# DDR_PHY register map
Vendor: Texas Instruments
Registers are 32-bit, access per field, reset 0x0 unless marked. A register's access mark holds for its fields unless they carry their own. Offsets are as the file gives them; [hi:lo] are bit positions; {n}, {i} and the like mark numbered series; 'fields as' and 'values as' point back to an identical list.

## DDR_PHY
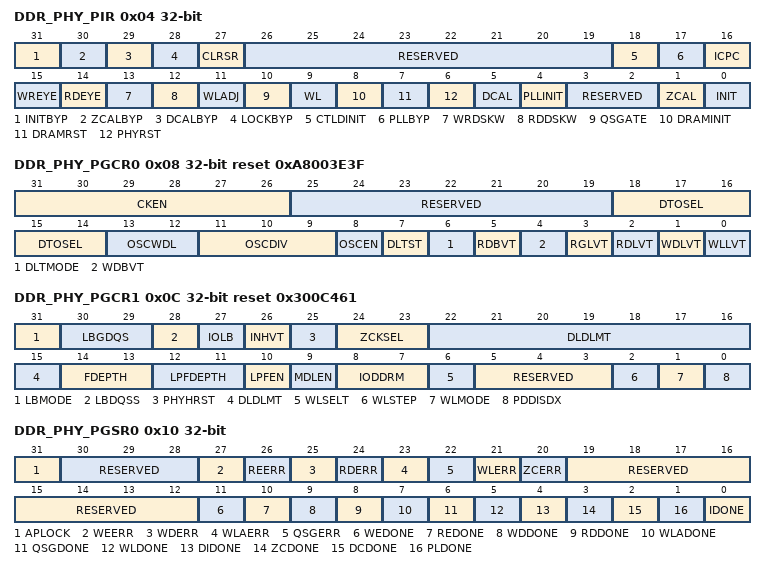
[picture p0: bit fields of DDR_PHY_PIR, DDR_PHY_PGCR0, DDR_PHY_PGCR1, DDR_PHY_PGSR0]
0x04 DDR_PHY_PIR
  [31] INITBYP rw — Initialization Bypass: Bypasses or stops, if set, all initialization routines currently running, including PHY initialization, DRAM initialization, and PHY training. Initialization may be triggered manually using INIT and the other relevant bits of the
  [30] ZCALBYP rw — Impedance Calibration Bypass: Bypasses or stops, if set, impedance calibration of all ZQ control blocks that automatically triggers after reset. Impedance calibration may be triggered manually using INIT and ZCAL bits of the
  [29] DCALBYP rw — Digital Delay Line (DDL) Calibration Bypass: Bypasses or stops, if set, DDL calibration that automatically triggers after reset. DDL calibration may be triggered manually using INIT and DCAL bits of the
  [28] LOCKBYP rw — PLL Lock Bypass: Bypasses or stops, if set, the waiting of PLLs to lock. PLL lock wait is automatically triggered after reset. PLL lock wait may be triggered manually using INIT and PLLLOCK bits of the
  [27] CLRSR rw — Clear Status Registers: A write of '1' to this bit will clear (reset to ‘0’) all status registers, including PGSR and DXnGSR. The clear status register bit is self-clearing. Note, this bit does not clear the PGSR.IDONE bit. If the IDONE bit is set it remains at 1’b1 to indicate the PUB has competed its task. This bit is primarily for debug purposes and is typically not needed during normal functional operation. It can be used when PGSR.IDONE=1, to manually clear the PGSR status bits, although starting a new init process will automatically clear the PGSR status bits. Or it can be used to manually clear the DXnGSR status bits, although starting a new data training process will automatically clear the DXnGSR status bits.
  [26:19] RESERVED ro — Returns zeros on reads.
  [18] CTLDINIT rw — Controller DRAM Initialization: Indicates if set that DRAM initialization will be performed by the controller. Otherwise if not set it indicates that DRAM initialization will be performed using the built-in initialization sequence or using software through the configuration port.
  [17] PLLBYP rw — PLL Bypass: A setting of 1 on this bit will put all PHY PLLs in bypass mode.
  [16] ICPC rw — Initialization Complete Pin Configuration: Specifies how the DFI initialization complete output pin (dfi_init_complete) should be used to indicate the status of initialization. Valid value are:
  [15] WREYE rw — Write Data Eye Training: Executes a PUB training routine to maximize the write data eye.
  [14] RDEYE rw — Read Data Eye Training: Executes a PUB training routine to maximize the read data eye.
  [13] WRDSKW rw — Write Data Bit Deskew: Executes a PUB training routine to deskew the DQ bits during write
  [12] RDDSKW rw — Read Data Bit Deskew: Executes a PUB training routine to deskew the DQ bits during read
  [11] WLADJ rw — Write Leveling Adjust (DDR3 Only): Executes a PUB training routine that readjusts the write latency used during write in case the write leveling routine changed the expected latency.
  [10] QSGATE rw — Read DQS Gate Training: Executes a PUB training routine to determine the optimum position of the read data DQS strobe for maximum system timing margins
  [9] WL rw — Write Leveling (DDR3 Only): Executes a PUB write leveling routine.
  [8] DRAMINIT rw — DRAM Initialization: Executes the DRAM initialization sequence
  [7] DRAMRST rw — DRAM Reset: Issues a reset to the DRAM (by driving the DRAM reset pin low) and wait 200us. This can be triggered in isolation or with the full DRAM initialization (DRAMINIT). For the later case, the reset is issued and 200us is waited before starting the full initialization sequence.
  [6] PHYRST rw — PHY Reset: Resets the AC and DATX8 modules by asserting the AC/DATX8 reset pin.
  [5] DCAL rw — Digital Delay Line (DDL) Calibration: Performs PHY delay line calibration.
  [4] PLLINIT rw — PLL Initialization: Executes the PLL initialization sequence which includes correct driving of PLL power-down, reset and gear shift pins, and then waiting for the PHY PLLs to lock.
  [3:2] RESERVED ro — Returns zeros on reads
  [1] ZCAL rw — Impedance Calibration: Performs PHY impedance calibration. When set the impedance calibration will be performed in parallel with PHY initialization (PLL initialization + DDL calibration + PHY reset).
  [0] INIT rw — Initialization Trigger: A write of '1' to this bit triggers the DDR system initialization, including PHY initialization, DRAM initialization, and PHY training. The exact initialization steps to be executed are specified in bits 1 to 15 of this register. A bit setting of 1 means the step will be executed as part of the initialization sequence, while a setting of ‘0’ means the step will be bypassed. The initialization trigger bit is self-clearing.
0x08 DDR_PHY_PGCR0 reset 0xA8003E3F
  [31:26] CKEN rw — CK Enable: Controls whether the CK going to the SDRAM is enabled (toggling) or disabled (static value) and whether the CK is inverted. Two bits for each of the up to three CK pairs. Valid values for the two bits are: TI recommends that this field be always programmed to 101010b.
  [25:19] RESERVED ro — Returns zeros on reads.
  [18:14] DTOSEL rw — Digital Test Output Select: Selects the PHY digital test output that should be driven onto PHY digital test output (phy_dto) pin: Valid values are:
  [13:12] OSCWDL rw — Oscillator Mode Write-Leveling Delay Line Select: Selects which of the two write leveling LCDLs is active. The delay select value of the inactive LCDL is set to zero while the delay select value of the active LCDL can be varied by the input write leveling delay select pin. Valid values are:
  [11:9] OSCDIV rw — Oscillator Mode Division: Specifies the factor by which the delay line oscillator mode output is divided down before it is output on the delay line digital test output pin dl_dto. Valid values are:
  [8] OSCEN rw — Oscillator Enable: Enables, if set, the delay line oscillation.
  [7] DLTST rw — Delay Line Test Start: A write of '1' to this bit will trigger delay line oscillator mode period measurement. This bit is not self clearing and needs to be reset to '0' before the measurement can be re-triggered.
  [6] DLTMODE rw — Delay Line Test Mode: Selects, if set, the delay line oscillator test mode.
  [5] RDBVT rw — Read Data BDL VT Compensation: Enables, if set the VT drift compensation of the read data bit delay lines
  [4] WDBVT rw — Write Data BDL VT Compensation: Enables, if set the VT drift compensation of the write data bit delay lines.
  [3] RGLVT rw — Read DQS Gating LCDL Delay VT Compensation: Enables, if set the VT drift compensation of the read DQS gating LCDL
  [2] RDLVT rw — Read DQS LCDL Delay VT Compensation: Enables, if set the VT drift compensation of the read DQS LCDL.
  [1] WDLVT rw — Write DQ LCDL Delay VT Compensation: Enables, if set the VT drift compensation of the write DQ LCDL.
  [0] WLLVT rw — Write Leveling LCDL Delay VT Compensation: Enables, if set, the VT drift compensation of the write leveling LCDL
0x0C DDR_PHY_PGCR1 reset 0x300C461
  [31] LBMODE rw — Loopback Mode: Indicates, if set, that the PHY/PUB is in loopback mode
  [30:29] LBGDQS rw — Loopback DQS Gating: Selects the DQS gating mode that should be used when the PHY is in loopback mode, including BIST loopback mode. Valid values are:
  [28] LBDQSS rw — Loopback DQS Shift: Selects how the read DQS is shifted during loopback to ensure that the read DQS is centered into the read data eye. Valid values are:
  [27] IOLB rw — I/O Loop-Back Select: Selects where inside the I/O the loop-back of signals happens. Valid values are:
  [26] INHVT rw — VT Calculation Inhibit: Inhibits calculation of the next VT compensated delay line values. A value of 1 will inhibit the VT calculation. This bit should be set to 1 during writes to the delay line registers. This bit should NOT be set to 1 until after PHY initialization completes
  [25] PHYHRST rw — PHY High-Speed Reset: A write of ‘0’ to this bit resets the AC and DATX8 macros without resetting PUB RTL logic. This bit is not self-clearing and a ‘1’ must be written to de-assert the reset
  [24:23] ZCKSEL rw — Impedance Clock Divider Select: Selects the divide ratio for the clock used by the impedance control logic relative to the clock used by the memory controller and SDRAM. Valid values are: TI recommends that this field be always programmed to 01b.
  [22:15] DLDLMT rw — Delay Line VT Drift Limit: Specifies the minimum change in the delay line VT drift in one direction which should result in the assertion of the delay line VT drift status signal (vt_drift). The limit is specified in terms of delay select values. A value of 0 disables the assertion of delay line VT drift status signal.
  [14:13] FDEPTH rw — Filter Depth: Specifies the number of measurements over which all AC and DATX8 initial period measurements, that happen after reset or when calibration is manually triggered, are averaged. Valid values are:
  [12:11] LPFDEPTH rw — Low-Pass Filter Depth: Specifies the number of measurements over which MDL period measurements are filtered. This determines the time constant of the low pass filter. Valid values are:
  [10] LPFEN rw — Low-Pass Filter Enable: Enables, if set, the low pass filtering of MDL period measurements.
  [9] MDLEN rw — Master Delay Line Enable: Enables, if set, the AC master delay line calibration to perform subsequent period measurements following the initial period measurements that are performed after reset or on when calibration is manually triggered. These additional measurements are accumulated and filtered as long as this bit remains high.
  [8:7] IODDRM rw — This field should be programmed to 1h if using DDR3 and 2h if using DDR3L.
  [6] WLSELT rw — Write Leveling Select Type: Selects the encoding type for the write leveling select signal depending on the desired setup/hold margins for the internal pipelines. Valid values are:
  [5:3] RESERVED ro — Return zeros on reads.
  [2] WLSTEP rw — Write Leveling Step: Specifies the number of delay step-size increments during each step of write leveling. Valid values are:
  [1] WLMODE rw — Write Leveling (Software) Mode: Indicates if set that the PHY is in software write leveling mode in which software executes single steps of DQS pulsing by writing '1' to
  [0] PDDISDX rw — Power Down Disabled Byte: Indicates if set that the PLL and I/Os of a disabled byte should be powered down
0x10 DDR_PHY_PGSR0 ro
  [31] APLOCK — AC PLL Lock: Indicates, if set, that AC PLL has locked. This is a direct status of the AC PLL lock pin
  [30:28] RESERVED — Returns zeros on reads.
  [27] WEERR — Write Eye Training Error: Indicates if set that there is an error in write eye training.
  [26] REERR — Read Eye Training Error: Indicates if set that there is an error in read eye training
  [25] WDERR — Write Bit Deskew Error: Indicates if set that there is an error in write bit deskew
  [24] RDERR — Read Bit Deskew Error: Indicates if set that there is an error in read bit deskew
  [23] WLAERR — Write Leveling Adjustment Error: Indicates if set that there is an error in write leveling adjustment
  [22] QSGERR — DQS Gate Training Error: Indicates if set that there is an error in DQS gate training.
  [21] WLERR — Write Leveling Error: Indicates if set that there is an error in write leveling.
  [20] ZCERR — Impedance Calibration Error: Indicates if set that there is an error in impedance calibration.
  [19:12] RESERVED — Returns zeros on reads.
  [11] WEDONE — Write Eye Training Done: Indicates if set that write eye training has completed
  [10] REDONE — Read Eye Training Done: Indicates if set that read eye training has completed
  [9] WDDONE — Write Bit Deskew Done: Indicates if set that write bit deskew has completed.
  [8] RDDONE — Read Bit Deskew Done: Indicates if set that read bit deskew has completed
  [7] WLADONE — Write Leveling Adjustment Done: Indicates if set that write leveling adjustment has completed
  [6] QSGDONE — DQS Gate Training Done: Indicates if set that DQS gate training has completed.
  [5] WLDONE — Write Leveling Done: Indicates if set that write leveling has completed.
  [4] DIDONE — DRAM Initialization Done: Indicates if set that DRAM initialization has completed
  [3] ZCDONE — Impedance Calibration Done: Indicates if set that impedance calibration has completed
  [2] DCDONE — Digital Delay Line (DDL) Calibration Done: Indicates if set that DDL calibration has completed
  [1] PLDONE — PLL Lock Done: Indicates if set that PLL locking has completed.
  [0] IDONE — Initialization Done: Indicates if set that the DDR system initialization has completed. This bit is set after all the selected initialization routines in
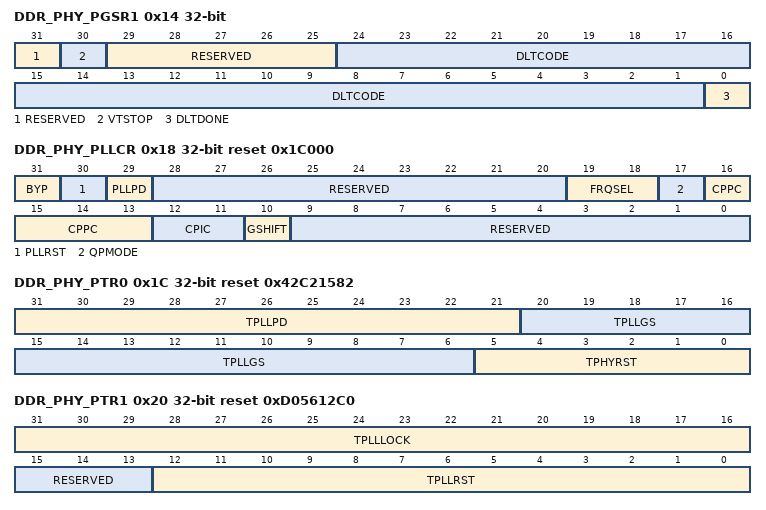
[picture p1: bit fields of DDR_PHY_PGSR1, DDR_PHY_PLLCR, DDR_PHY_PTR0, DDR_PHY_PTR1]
0x14 DDR_PHY_PGSR1 ro
  [31] RESERVED — Returns zeros on reads.
  [30] VTSTOP — VT Stop: Indicates if set that the VT calculation logic has stopped computing the next values for the VT compensated delay line values. After assertion of the PGCR.INHVT, the VTSTOP bit should be read to ensure all VT compensation logic has stopped computations before writing to the delay line registers
  [29:25] RESERVED — Returns zeros on reads.
  [24:1] DLTCODE — Delay Line Test Code: Returns the code measured by the PHY control block that corresponds to the period of the AC delay line digital test output.
  [0] DLTDONE — Delay Line Test Done: Indicates, if set, that the PHY control block has finished doing period measurement of the AC delay line digital test output
0x18 DDR_PHY_PLLCR reset 0x1C000
  [31] BYP rw — PLL Bypass: Bypasses the PLL if set to 1.
  [30] PLLRST rw — PLL Rest: Resets the PLLs by driving the PLL reset pin. This bit is not self-clearing and a ‘0’ must be written to de-assert the reset.
  [29] PLLPD rw — PLL Power Down: Puts the PLLs in power down mode by driving the PLL power down pin. This bit is not self-clearing and a ‘0’ must be written to de-assert the power-down
  [28:20] RESERVED ro — Returns zeros on reads.
  [19:18] FRQSEL rw — PHY PLL reference frequency select: Selects the operating range of the PHY PLL. Valid values are:
  [17] QPMODE rw — PLL Quadrature Phase Mode: Enables, if set, the quadrature phase clock outputs. This mode is not used in this version of the PHY
  [16:13] CPPC rw — Charge Pump Proportional Current Control
  [12:11] CPIC rw — Charge Pump Integrating Current Control
  [10] GSHIFT ro — Gear Shift: Enables, if set, rapid locking mode.
  [9:0] RESERVED ro — Reads return zeros
0x1C DDR_PHY_PTR0 rw reset 0x42C21582
  [31:21] TPLLPD — PLL Power-Down Time: Number of VBUSP_CLK cycles that the PLL must remain in power-down mode, that is, number of clock cycles from when PLL power-down pin is asserted to when PLL power-down pin is de-asserted. This must correspond to a value that is equal to or more than 1us. Default value corresponds to 1us.
  [20:6] TPLLGS — PLL Gear Shift Time: Number of VBUSP_CLK cycles from when the PLL reset pin is de-asserted to when the PLL gear shift pin is de-asserted. This must correspond to a value that is equal to or more than 4us. Default value corresponds to 4us.
  [5:0] TPHYRST — PHY Reset Time: Number of VBUSP_CLK cycles that the PHY reset must remain asserted after PHY calibration is done before the reset to the PHY is de-asserted. This is used to extend the reset to the PHY so that the reset is asserted for some clock cycles after the clocks are stable. TI recommends setting this to 15.
0x20 DDR_PHY_PTR1 reset 0xD05612C0
  [31:16] TPLLLOCK rw — PLL Lock Time: Number of VBUSP_CLK cycles for the PLL to stabilize and lock, that is, number of clock cycles from when the PLL reset pin is de-asserted to when the PLL has lock and is ready for use. This must correspond to a value that is equal to or more than 100us. Default value corresponds to 100us
  [15:13] RESERVED ro — Reads return zeros.
  [12:0] TPLLRST rw — PLL Reset Time: Number of VBUSP_CLK cycles that the PLL must remain in reset mode, that is, number of clock cycles from when PLL power-down pin is de-asserted and PLL reset pin is asserted to when PLL reset pin is de-asserted. This must correspond to a value that is equal to or more than 9 us. Default value corresponds to 9 us.
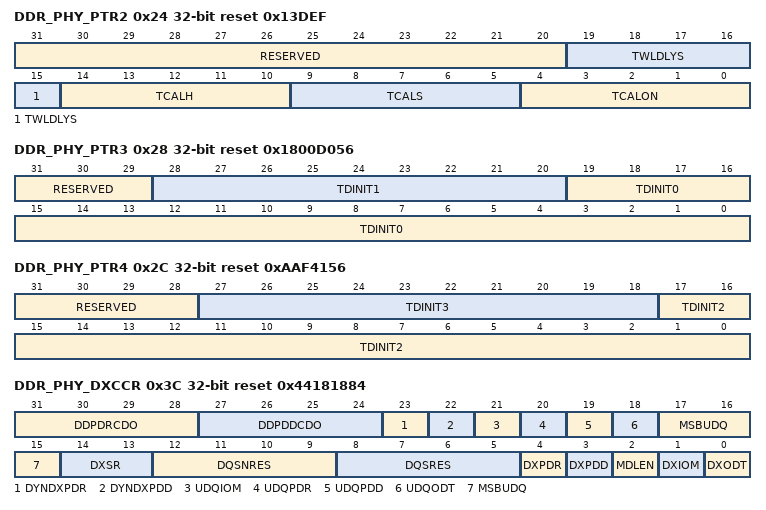
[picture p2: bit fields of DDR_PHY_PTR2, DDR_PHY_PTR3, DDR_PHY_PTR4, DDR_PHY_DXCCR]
0x24 DDR_PHY_PTR2 rw reset 0x13DEF
  [31:20] RESERVED — Reads return zeros.
  [19:15] TWLDLYS — Write Leveling Delay Settling Time: Number of controller clock cycles from when a new value of the write leveling delay is applies to the LCDL to when to DQS high is driven high. This allows the delay to settle
  [14:10] TCALH — Calibration Hold Time: Number of controller clock cycles from when the clock was disabled (cal_clk_en deasserted) to when calibration is enable (cal_en asserted).
  [9:5] TCALS — Calibration Setup Time: Number of controller clock cycles from when calibration is enabled (cal_en asserted) to when the calibration clock is asserted again (cal_clk_en asserted).
  [4:0] TCALON — Calibration On Time: Number of controller clock cycles that the calibration clock is enabled (cal_clk_en asserted).
0x28 DDR_PHY_PTR3 reset 0x1800D056
  [31:29] RESERVED ro — Reads return zeros.
  [28:20] TDINIT1 rw — DRAM Initialization Time 1: DRAM initialization time in DRAM clock cycles corresponding to the following: DDR3 = CKE high time to first command (tRFC + 10 ns or 5 tCK, whichever is bigger) Default value corresponds to DDR3 tRFC of 360ns at 1066 MHz tDINIT1 = (tCKE/tCK)-1
  [19:0] TDINIT0 rw — DRAM Initialization Time 0: DRAM initialization time in DRAM clock cycles corresponding to the following: DDR3 = CKE low time with power and clock stable (500 us)
0x2C DDR_PHY_PTR4 reset 0xAAF4156
  [31:28] RESERVED ro — Reads return zeros.
  [27:18] TDINIT3 rw — DRAM Initialization Time 3: DRAM initialization time in DRAM clock cycles corresponding to the following: DDR3 = Time from ZQ initialization command to first command (1 us) Default value corresponds to the DDR3 640ns at 1066 MHz.
  [17:0] TDINIT2 rw — DRAM Initialization Time 2: DRAM initialization time in DRAM clock cycles corresponding to the following: DDR3 = Reset low time (200 us on power-up or 100 ns after power-up) Default value corresponds to DDR3 200 us at 1066 MHz.
0x38 DDR_PHY_ACIOCR reset 0x33C03812
  [31:30] ACSR rw — Address/Command Slew Rate: Selects slew rate of the I/O for all address and command pins. 00 = very fast (use as default for DDR3 and DDR3L) 01 = fast 10 = medium 11 = slow
0x3C DDR_PHY_DXCCR rw reset 0x44181884
  [31:28] DDPDRCDO — Dynamic Data Power Down Receiver Count Down Offset: Offset applied in calculating window of time where receiver is powered up
  [27:24] DDPDDCDO — Dynamic Data Power Down Driver Count Down Offset: Offset applied in calculating window of time where driver is powered up
  [23] DYNDXPDR — Data Power Down Receiver: Dynamically powers down, when set, the input receiver on I/O for the DQ pins of the active DATX8 macros. Applies only when DXPDR and DXnGCR.DXPDR are not set to 1.
  [22] DYNDXPDD — Dynamic Data Power Down Driver: Dynamically powers down, when set, the output driver on I/O for the DQ pins of the active DATX8 macros. Applies only when DXPDD and DXnGCR.DXPDD are not set to 1.
  [21] UDQIOM — Unused DQ I/O Mode: Selects SSTL mode (when set to 0) or CMOS mode (when set to 1) of the I/O for unused DQ pins.
  [20] UDQPDR — Unused DQ Power Down Receiver: Powers down, when set, the input receiver on the I/O for unused DQ pins.
  [19] UDQPDD — Unused DQ Power Down Driver: Powers down, when set, the output driver on the I/O for unused DQ pins.
  [18] UDQODT — Unused DQ On-Die Termination: Enables, when set, the on-die termination on the I/O for unused DQ pins.
  [17:15] MSBUDQ — Most Significant Byte Unused DQs: Specifies the number of DQ bits that are not used in the most significant byte. The used (valid) bits for this byte are [8-MSBDQ- 1:0]. To disable the whole byte, use the DXnGCR.DXEN register.
  [14:13] DXSR — Data Slew Rate: Selects slew rate of the I/O for DQ, DM, and DQS/DQS# pins of all DATX8 macros. 00 = very fast (use as default for DDR3 and DDR3L) 01 = fast 10 = medium 11 = slow
  [12:9] DQSNRES — DQS# Resistor: Selects the on-die pull-up/pull-down resistor for DQS# pins. Same encoding as DQSRES.
  [8:5] DQSRES — DQS Resistor: Selects the on-die pull-down/pull-up resistor for DQS pins. DQSRES[3] selects pull-down (when set to 0) or pull-up (when set to 1). DQSRES[2:0] selects the resistor value as follows: 000 = Open: On-die resistor disconnected (use external resistor) 001 = 688 ohms 010 = 611 ohms 011 = 550 ohms 100 = 500 ohms 101 = 458 ohms 110 = 393 ohms 111 = 344 ohms
  [4] DXPDR — Data Power Down Receiver: Powers down, when set, the input receiver on I/O for DQ, DM, and DQS/DQS# pins of all DATX8 macros. This bit is ORed with the PDR configuration bit of the individual DATX8.
  [3] DXPDD — Data Power Down Driver: Powers down, when set, the output driver on I/O for DQ,DM, and DQS/DQS# pins of all DATX8 macros. This bit is ORed with the PDD configuration bit of the individual DATX8.
  [2] MDLEN — Master Delay Line Enable: Enables, if set, all DATX8 master delay line calibration to perform subsequent period measurements following the initial period measurements that are performed after reset or on when calibration is manually triggered. These additional measurements are accumulated and filtered as long as this bit remains high. This bit is ANDed with the MDLEN bit in the individual DATX8
  [1] DXIOM — Data I/O Mode: Selects SSTL mode (when set to 0) or CMOS mode (when set to 1) of the I/O for DQ, DM, and DQS/DQS# pins of all DATX8 macros. This bit is ORed with the IOM configuration bit of the individual DATX8.
  [0] DXODT — Data On-Die Termination: Enables, when set, the on-die termination on the I/O for DQ, DM, and DQS/DQS# pins of all DATX8 macros. This bit is ORed with the ODT configuration bit of the individual DATX8
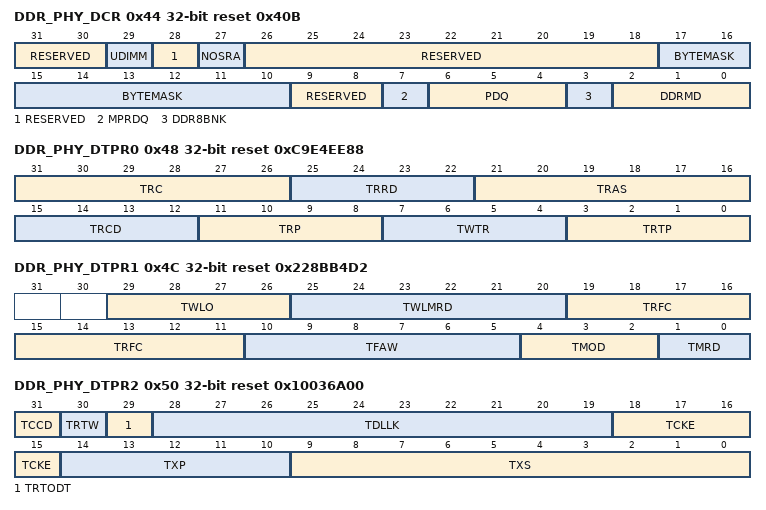
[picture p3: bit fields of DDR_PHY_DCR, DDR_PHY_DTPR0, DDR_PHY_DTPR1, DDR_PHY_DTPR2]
0x44 DDR_PHY_DCR reset 0x40B
  [31:30] RESERVED ro — Reads return zeros.
  [29] UDIMM rw — Un-buffered DIMM Address Mirroring: Indicates if set that there is address mirroring on the second rank of an un-buffered DIMM (the rank connected to CS1).
  [28] RESERVED ro — Reads return zeros.
  [27] NOSRA rw — No Simultaneous Rank Access: Specifies if set that simultaneous rank access on the same clock cycle is not allowed. This means that multiple chip select signals will not be asserted at the same time. This bit must be set if address mirroring is enabled in
  [26:18] RESERVED ro — Reads return zeros.
  [17:10] BYTEMASK rw — Byte Mask: Mask applied to all beats of read data on all bytes lanes during read DQS gate training. This allows training to be conducted based on selected bit(s) from the byte lanes. Valid values for each bit are: Note that this mask in DDR3 MPR operation mode as well and must be in keeping with the PDQ field setting. TI recommends that this field be always programmed to 0000 0001b.
  [9:8] RESERVED ro — Reads return zeros.
  [7] MPRDQ rw — Multi-Purpose Register (MPR) DQ (DDR3 Only): Specifies the value that is driven on non-primary DQ pins during MPR reads. Valid values are: TI recommends that this bit be always programmed to 0.
  [6:4] PDQ rw — Primary DQ (DDR3 Only): Specifies the DQ pin in a byte that is designated as a primary pin for Multi-Purpose Register (MPR) reads. Valid values are 0 to 7 for DQ[0] to DQ[7], respectively. TI recommends that this field be always programmed to 000b.
  [3] DDR8BNK rw — DDR 8-Bank: Indicates if set that the SDRAM used has 8 banks.
  [2:0] DDRMD rw — DDR Mode: Set to 3h for DDR3 mode.
0x48 DDR_PHY_DTPR0 rw reset 0xC9E4EE88
  [31:26] TRC — Activate to activate command delay (same bank). Valid values are 2 to 63
  [25:22] TRRD — Activate to activate command delay (different banks). Valid values are 1 to 15.
  [21:16] TRAS — Activate to precharge command delay. Valid values are 2 to 63
  [15:12] TRCD — Activate to read or write delay. Minimum time from when an activate command is issued to when a read or write to the activated row can be issued. Valid values are 2 to 15.
  [11:8] TRP — Precharge command period: The minimum time between a precharge command and any other command. Valid values are 2 to 15.
  [7:4] TWTR — Internal write to read command delay. Valid values are 1 to 15.
  [3:0] TRTP — Internal read to precharge command delay. Valid values are 2 to 15.
0x4C DDR_PHY_DTPR1 reset 0x228BB4D2
  [29:26] TWLO rw — Write leveling output delay: Number of clock cycles from when write leveling DQS is driven high by the PHY to when the results from the SDRAM on DQ is sampled by the PHY. This must include the SDRAM tWLO timing parameter plus the round trip delay from the DUT to SDRAM back to the DUT. TI recommends that this field always be programmed to 12 decimal.
  [25:20] TWLMRD rw — Minimum delay from when write leveling mode is programmed to the first DQS/DQS# rising edge
  [19:11] TRFC rw — Refresh-to-Refresh: Indicates the minimum time, in clock cycles, between two refresh commands or between a refresh and an active command. This is derived from the minimum refresh interval from the data sheet, tRFC(min), divided by the clock cycle time.
  [10:5] TFAW rw — 4-bank activate period. No more than 4-bank activate commands may be issued in a given tFAW period. Valid values are 2 to 63.
  [4:2] TMOD rw — Load mode update delay. The minimum time between a load mode register command and a non-load mode register command. Valid values are:
  [1:0] TMRD rw — Load mode cycle time: The minimum time between a load mode register command and any other command. For DDR3 this is the minimum time between two load mode register commands. the value used for tMRD is 4 plus the value programmed in these bits, that is, tMRD ranges from 4 to 7.
0x50 DDR_PHY_DTPR2 rw reset 0x10036A00
  [31] TCCD — Read to read and write to write command delay. Valid values are:
  [30] TRTW — Read to Write command delay. This parameter is only used when the PHY issues commands during initialization and leveling. During normal operation, the controller issues commands to the SDRAM and uses the timing parameters programmed in the controller. TI recommends that this bit be always set to 1 to provide additional margin during PHY initiated initialization/leveling.
  [29] TRTODT — Read to ODT delay. This parameter is only used when the PHY issues commands during initialization and leveling. During normal operation, the controller issues commands to the SDRAM and uses the timing parameters programmed in the controller. TI recommends that this bit be always set to 0.
  [28:19] TDLLK — DLL locking time. Valid values are 2 to 1023.
  [18:15] TCKE — CKE minimum pulse width. Also specifies the minimum time that the SDRAM must remain in power down or self refresh mode. This parameter must be set to the value of tCKESR which is usually bigger than the value of tCKE. Valid values are 2 to 15.
  [14:10] TXP — Power down exit delay. The minimum time between a power down exit command and any other command. This parameter must be set to the maximum of the various minimum power down exit delay parameters specified in the SDRAM data sheet, that is, max(tXP, tXPDLL). Valid values are 2 to 31.
  [9:0] TXS — Self refresh exit delay. The minimum time between a self refresh exit command and any other command. This parameter must be set to the maximum of the various minimum self refresh exit delay parameters specified in the SDRAM data sheet, that is, (tXS, tXSDLL) for DDR3. Valid values are 2 to 1023.
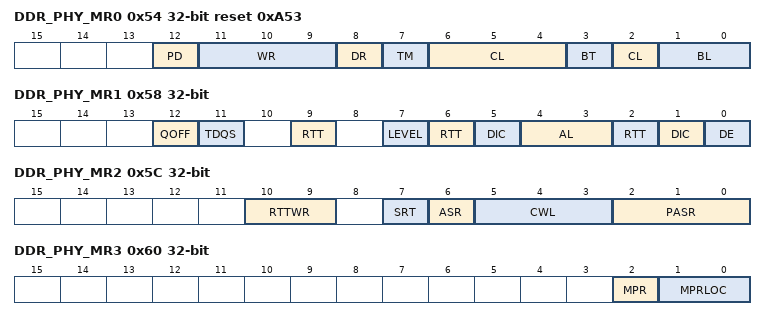
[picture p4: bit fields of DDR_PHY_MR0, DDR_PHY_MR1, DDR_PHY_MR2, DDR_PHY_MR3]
0x54 DDR_PHY_MR0 reset 0xA53
  [12] PD rw — Power-Down Control: Controls the exit time for power-down modes. This must always be set to 1.
  [11:9] WR rw — Write Recovery: This is the value of the write recovery in clock cycles. It is calculated by dividing the data sheet write recovery time, tWR (ns) by the data sheet clock cycle time, tCK (ns) and rounding up a non-integer value to the next integer. Valid values are: All other settings are reserved and should not be used.
  [8] DR rw — DLL Reset: Writing a ‘1’ to this bit will reset the SDRAM DLL. This bit is self-clearing, that is, it returns back to ‘0’ after the DLL reset has been issued.
  [7] TM rw — Operating Mode: Always set to 0 for normal operating mode.
  [6:4] CL rw — CAS Latency: The delay, in clock cycles, between SDRAM read command to data available. Valid values are: All other settings are reserved and should not be used.
  [3] BT rw — Burst type: Set to 0 for sequential burst (interleaved burst is not supported)
  [2] CL rw — This is the least significant bit of the CL field. For description, see bits [6-4].
  [1:0] BL rw — Burst Length: Determines the maximum number of column locations that can be accessed during a given read or write command. Set to 0 for a fixed burst length of 8 (other burst lengths are not supported)
0x58 DDR_PHY_MR1
  [12] QOFF rw — Output Enable/Disable: Program to ‘0’ for all outputs to function as normal.
  [11] TDQS rw — Termination Data Strobe: This must always be set to 0.
  [9] RTT rw — On Die Termination: Selects the effective resistance for SDRAM on die termination. Valid values are: All other settings are reserved and should not be used
  [7] LEVEL rw — Write Leveling Enable: Enables write-leveling when set.
  [6] RTT rw — On Die Termination: Selects the effective resistance for SDRAM on die termination. Valid values are: All other settings are reserved and should not be used
  [5] DIC rw — Output Driver Impedance Control: Controls the output drive strength. Valid values are:
  [4:3] AL rw — Posted CAS Additive Latency: the controller does not support this feature. This must always be set to 0.
  [2] RTT rw — On Die Termination: Selects the effective resistance for SDRAM on die termination. Valid values are: All other settings are reserved and should not be used
  [1] DIC rw — Output Driver Impedance Control: Controls the output drive strength. Valid values are:
  [0] DE rw — DLL Enable/Disable: Enable (0) or disable (1) the DLL. DLL must be enabled for normal operation.
0x5C DDR_PHY_MR2
  [10:9] RTTWR rw — Dynamic ODT: Selects RTT for dynamic ODT. Valid values are:
  [7] SRT rw — Self-Refresh Temperature Range: Selects either normal (‘0’) or extended (‘1’) operating temperature range during self-refresh.
  [6] ASR rw — Auto Self-Refresh: When enabled (‘1’), SDRAM automatically provides self-refresh power management functions for all supported operating temperature values. Otherwise the SRT bit must be programmed to indicate the temperature range.
  [5:3] CWL rw — CAS Write Latency: The delay, in clock cycles, between when the SDRAM registers a write command to when write data is available. Valid values are: All other settings are reserved and should not be used
  [2:0] PASR rw — Partial Array Self Refresh: Specifies that data located in areas of the array beyond the specified location will be lost if self refresh is entered.
0x60 DDR_PHY_MR3
  [2] MPR rw — Multi-Purpose Register Enable: Enables, if set, that read data should come from the Multi-Purpose Register. Otherwise read data come from the DRAM array.
  [1:0] MPRLOC rw — Multi-Purpose Register (MPR) Location: Selects MPR data location: Valid value are:
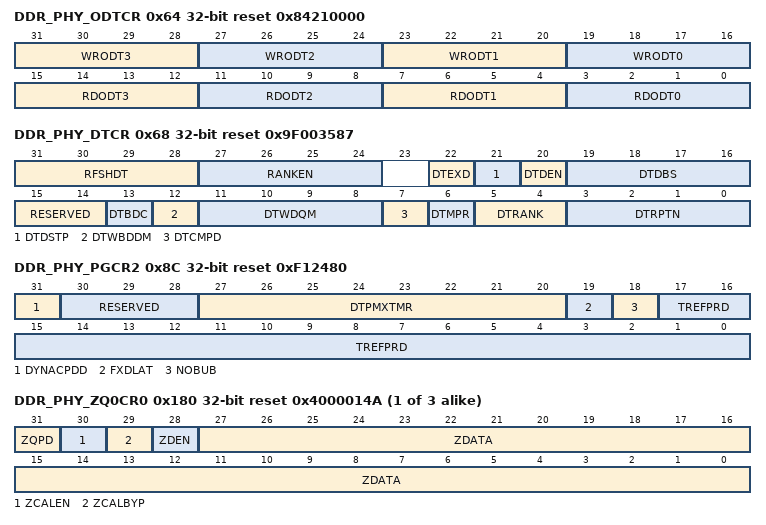
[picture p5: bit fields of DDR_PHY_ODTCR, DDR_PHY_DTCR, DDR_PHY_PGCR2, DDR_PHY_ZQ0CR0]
0x64 DDR_PHY_ODTCR rw reset 0x84210000
  [31:28] WRODT3 — Write ODT: Specifies whether ODT should be enabled (‘1’) or disabled (‘0’) on each of the up to four ranks when a write command is sent to rank n. WRODT0, WRODT1, WRODT2, and WRODT3 specify ODT settings when a write is to rank 0, rank 1, rank 2, and rank 3, respectively. The four bits of each field each represent a rank, the LSB being rank 0 and the MSB being rank 3. Default is to enable ODT only on rank being written to
  [27:24] WRODT2 — See description for WRODT3.
  [23:20] WRODT1 — See description for WRODT3.
  [19:16] WRODT0 — See description for WRODT3.
  [15:12] RDODT3 — Read ODT: Specifies whether ODT should be enabled (‘1’) or disabled (‘0’) on each of the up to four ranks when a read command is sent to rank n. RDODT0, RDODT1, RDODT2, and RDODT3 specify ODT settings when a read is to rank 0, rank 1, rank 2, and rank 3, respectively. The four bits of each field each represent a rank, the LSB being rank 0 and the MSB being rank 3. Default is to disable ODT during reads.
  [11:8] RDODT2 — See description for RDODT3.
  [7:4] RDODT1 — See description for RDODT3.
  [3:0] RDODT0 — See description for RDODT3.
0x68 DDR_PHY_DTCR reset 0x9F003587
  [31:28] RFSHDT rw — Refresh During Training: A non-zero value specifies that a burst of refreshes equal to the number specified in this field should be sent to the SDRAM after training each rank except the last rank
  [27:24] RANKEN rw — Rank Enable: Specifies the ranks that are enabled for data-training. Bit 0 controls rank 0, bit 1 controls rank 1, bit 2 controls rank 2, and bit 3 controls rank 3. Setting the bit to ‘1’ enables the rank, and setting it to ‘0’ disables the rank.
  [22] DTEXD rw — Data Training Extended Write DQS: Enables, if set, an extended write DQS whereby two additional pulses of DQS are added as post-amble to a burst of writes. Generally this should only be enabled when running read bit deskew with the intention of performing read eye deskew prior to running write leveling adjustment
  [21] DTDSTP rw — Data Training Debug Step: A write of 1 to this bit steps the data training algorithm through a single step. This bit is self-clearing
  [20] DTDEN rw — Data Training Debug Enable: Enables, if set, the data training debug mode
  [19:16] DTDBS rw — Data Training Debug Byte Select: Selects the byte during data training debug mod
  [15:14] RESERVED ro — Returns zeros on reads.
  [13] DTBDC rw — Data Training Bit Deskew Centering: Enables, if set, eye centering capability during write and read bit deskew training.
  [12] DTWBDDM rw — Data Training Write Bit Deskew Data Mask. If set it enables write bit deskew of the data mask
  [11:8] DTWDQM rw — Training WDQ Margin: Defines how close to 0 or how close to 2*(wdq calibration_value) the WDQ lcdl can be moved during training. Basically defines how much timing margin.
  [7] DTCMPD rw — Data Training Compare Data: Specifies, if set, that DQS gate training should also check if the returning read data is correct. Otherwise data-training only checks if the correct number of DQS edges were returned.
  [6] DTMPR rw — Data Training Using MPR (DDR3 Only): Specifies, if set, that DQS gate training should use the SDRAM Multi-Purpose Register (MPR) register. Otherwise data training is performed by first writing to some locations in the SDRAM and then reading them back.
  [5:4] DTRANK rw — Data Training Rank: Selects the SDRAM rank to be used during data bit deskew and eye centering
  [3:0] DTRPTN rw — Data Training Repeat Number: Repeat number used to confirm stability of DDR write or read
0x8C DDR_PHY_PGCR2 reset 0xF12480
  [31] DYNACPDD rw — Dynamic AC Power Down Driver: Powers down, when set, the output driver on I/O for the address and bank address lines
  [30:28] RESERVED ro — These bits should be always programmed to 0.
  [27:20] DTPMXTMR rw — Data Training PUB Mode Timer Exit: Specifies the number of controller clocks to wait when entering and exiting pub mode data training. The default value ensures controller refreshes do not cause memory model errors when entering and exiting data training. The value should be increased if controller initiated SDRAM ZQ short or long operation may occur just before or just after the execution of data training.
  [19] FXDLAT rw — Fixed Latency: Specified whether all reads should be returned to the controller with a fixed read latency. Enabling fixed read latency increases the read latency. Valid values are: Fixed read latency is calculated as (12 + (maximum DXnGTR.RxDGSL)/2) half data rate clock cycles.
  [18] NOBUB rw — No Bubbles: Specified whether reads should be returned to the controller with no bubbles. Enabling no-bubble reads increases the read latency. Valid values are:
  [17:0] TREFPRD rw — Refresh Period: Indicates the period in clock cycles after which the PUB has to issue a refresh command to the SDRAM. This is derived from the maximum refresh interval from the data sheet, tRFC(max) or REFI, divided by the clock cycle time. A further 400 clocks must be subtracted from the derived number to account for command flow and missed slots of refreshes in the internal PUB blocks. The default corresponds to DDR3 9*7.8us at 1066MHz (DDR3-2133) when a burst of 9 refreshes are issued at every refresh interval. TI recommends tREFPRD be programmed to 5*tREFI.
{0x180+0x10*i} DDR_PHY_ZQ{i}CR0 rw reset 0x4000014A (i=0..2)
  [31] ZQPD — ZQ Power Down: Powers down, if set, the impedance control block.
  [30] ZCALEN — Impedance Calibration Enable: Enables if set the impedance calibration of the ZQn control block when impedance calibration is triggered using either the ZCAL bit of
  [29] ZCALBYP — Impedance Calibration Bypass: Bypasses, if set, impedance calibration of the ZQn control block when impedance calibration is already in progress. Impedance calibration can be disabled prior to trigger by using the ZCALEN bit.
  [28] ZDEN — Impedance Over-ride Enable: When this bit is set, it allows users to directly drive the impedance control using the data programmed in the ZDATA field. Otherwise, the control is generated automatically by the impedance control logic
  [27:0] ZDATA — Impedance Over-Ride Data: Data used to directly drive the impedance control. ZDATA field mapping is as follows:
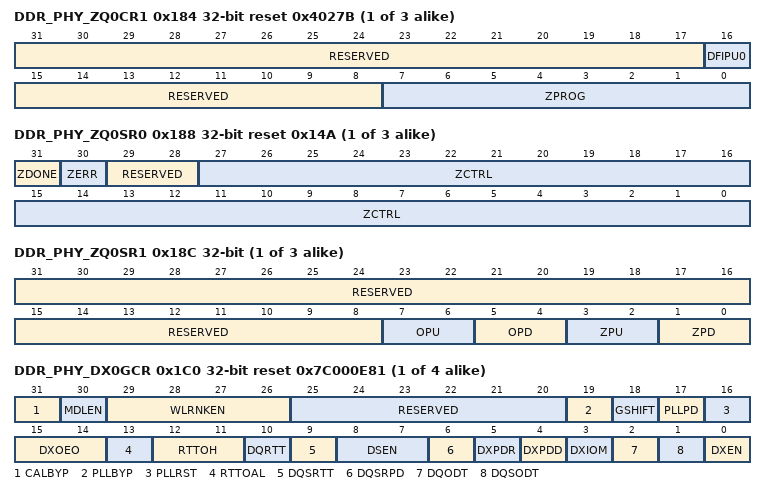
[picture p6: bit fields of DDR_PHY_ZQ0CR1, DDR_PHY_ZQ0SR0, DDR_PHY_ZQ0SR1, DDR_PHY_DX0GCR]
{0x184+0x10*i} DDR_PHY_ZQ{i}CR1 reset 0x4027B (i=0..2)
  [31:17] RESERVED ro — Returns zeros on reads.
  [16] DFIPU0 ro — Impedance Calibration Enable: Setting to 1 enables the PHY to request periodic updates to compensate for VT drifts that might result in decreased timing margin. TI recommends this be set to 1.
  [15:8] RESERVED ro — Returns zeros on reads.
  [7:0] ZPROG rw — Impedance Divide Ratio: Selects the external resistor divide ratio to be used to set the output impedance and the on-die termination as follows:
{0x188+0x10*i} DDR_PHY_ZQ{i}SR0 ro reset 0x14A (i=0..2)
  [31] ZDONE — Impedance Calibration Done: Indicates that impedance calibration has completed.
  [30] ZERR — Impedance Calibration Error: If set, indicates that there was an error during impedance calibration.
  [29:28] RESERVED — Returns zeros on reads.
  [27:0] ZCTRL — Impedance Control: Current value of impedance control. ZCTRL field mapping is as follows:
{0x18C+0x10*i} DDR_PHY_ZQ{i}SR1 ro (i=0..2)
  [31:8] RESERVED — Returns zeros on reads.
  [7:6] OPU — On-die termination (ODT) pull-up calibration status. Similar status encodings as ZPD.
  [5:4] OPD — On-die termination (ODT) pull-down calibration status. Similar status encodings as ZPD.
  [3:2] ZPU — Output impedance pull-up calibration status. Similar status encodings as ZPD.
  [1:0] ZPD — Output impedance pull-down calibration status. Valid status encodings are:
{0x1C0+0x40*i} DDR_PHY_DX{i}GCR reset 0x7C000E81 (i=0..3)
  [31] CALBYP rw — Calibration Bypass: Prevents, if set, period measurement calibration from automatically triggering after PHY initialization.
  [30] MDLEN rw — Master Delay Line Enable: Enables, if set, the DATX8 master delay line calibration to perform subsequent period measurements following the initial period measurements that are performed after reset or when calibration is manually triggered. These additional measurements are accumulated and filtered as long as this bit remains high. This bit is ANDed with the common DATX8 MDL enable bit.
  [29:26] WLRNKEN rw — Write Level Rank Enable: Specifies the ranks that should be write leveled for this byte. Write leveling responses from ranks that are not enabled for write leveling for a particular byte are ignored and write leveling is flagged as done for these ranks. WLRKEN[0] enables rank 0, [1] enables rank 1, [2] enables rank 2, and [3] enables rank 3.
  [25:20] RESERVED ro — Reads return zeros
  [19] PLLBYP rw — PLL Bypass: Puts the byte PLL in bypass mode by driving the PLL bypass pin. This bit is not self-clearing and a '0' must be written to de-assert the bypass. This bit is ORed with the global BYP configuration bit in
  [18] GSHIFT rw — Gear Shift: Enables, if set, rapid locking mode on the byte PLL
  [17] PLLPD rw — PLL Power Down: Puts the byte PLL in power down mode by driving the PLL power down pin. This bit is not self-clearing and a '0' must be written to de-assert the power-down. This bit is ORed with the global PLLPD configuration bit in
  [16] PLLRST rw — PLL Rest: Resets the byte PLL by driving the PLL reset pin. This bit is not selfclearing and a '0' must be written to de-assert the reset. This bit is ORed with the global PLLRST configuration bit in
  [15:14] DXOEO rw — Data Byte Output Enable Override: Specifies whether the output I/O output enable for the byte lane should be set to a fixed value. Valid values are:
  [13] RTTOAL rw — RTT On Additive Latency: Indicates when the ODT control of DQ/DQS SSTL I/Os is set to the value in DQODT/DQSODT during read cycles. Valid values are:
  [12:11] RTTOH rw — RTT Output Hold: Indicates the number of clock cycles (from 0 to 3) after the read data postamble for which ODT control should remain set to DQSODT for DQS or DQODT for DQ/DM before disabling it (setting it to ‘0’) when using dynamic ODT control. ODT is disabled almost RTTOH clock cycles after the read postamble
  [10] DQRTT rw — DQ Dynamic RTT Control: Indicates, if set, that the ODT control of DQ/DM SSTL I/Os be dynamically controlled by setting it to the value in DQODT during reads and disabling it (setting it to ‘0’) during any other cycle. If this bit is not set, then the ODT control of DQ SSTL I/Os is always set to the value in DQODT.
  [9] DQSRTT rw — DQS Dynamic RTT Control: Indicates, if set, that the ODT control of DQS SSTL I/Os be dynamically controlled by setting it to the value in DQSODT during reads and disabling it (setting it to ‘0’) during any other cycle. If this bit is not set, then the ODT control of DQS SSTL I/Os is always set to the value in DQSODT field
  [8:7] DSEN rw — Write DQS Enable: Controls whether the write DQS going to the SDRAM is enabled (toggling) or disabled (static value) and whether the DQS is inverted. DQS# is always the inversion of DQS. These values are valid only when DQS/DQS# output enable is on, otherwise the DQS/DQS# is tri-stated. Valid settings are:
  [6] DQSRPD rw — DQSR Power Down: Powers down, if set, the PDQSR cell.
  [5] DXPDR rw — Data Power Down Receiver: Powers down, when set, the input receiver on I/O for DQ, DM, and DQS/DQS# pins of the byte.
  [4] DXPDD rw — Data Power Down Driver: Powers down, when set, the output driver on I/O for DQ, DM, and DQS/DQS# pins of the byte.
  [3] DXIOM rw — Data I/O Mode: Selects SSTL mode (when set to 0) or CMOS mode (when set to 1) of the I/O for DQ, DM, and DQS/DQS# pins of the byte.
  [2] DQODT rw — Data On-Die Termination: Enables, when set, the on-die termination on the I/O for DQ and DM pins of the byte.
  [1] DQSODT rw — DQS On-Die Termination: Enables, when set, the on-die termination on the I/O for DQS/DQS# pin of the byte
  [0] DXEN rw — Data Byte Enable: Enables if set the data byte. Setting this bit to '0' disables the byte, that is, the byte is not used in PHY initialization or training and is ignored during SDRAM read/write operations. Note: Software-initiated PHY initialization and leveling is only required after ECC has been enabled in the PHY by writing to
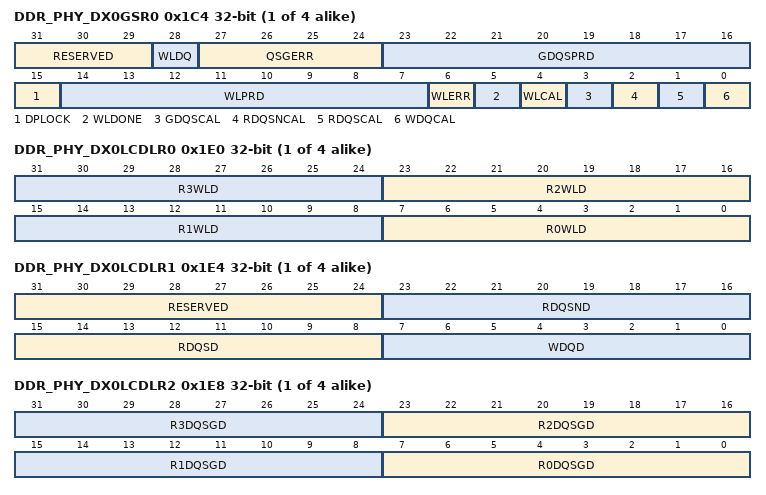
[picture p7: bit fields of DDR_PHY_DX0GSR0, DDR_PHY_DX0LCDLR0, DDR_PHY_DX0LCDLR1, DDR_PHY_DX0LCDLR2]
{0x1C4+0x40*i} DDR_PHY_DX{i}GSR0 ro (i=0..3)
  [31:29] RESERVED — Reads return zeros.
  [28] WLDQ — Write Leveling DQ Status: Captures the write leveling DQ status from the DRAM during software write leveling
  [27:24] QSGERR — DQS Gate Training Error: Indicates if set that there is an error in DQS gate training. One bit for each of the up to 4 ranks
  [23:16] GDQSPRD — Read DQS gating Period: Returns the DDR clock period measured by the read DQS gating LCDL during calibration. This value is PVT compensated
  [15] DPLOCK — DATX8 PLL Lock: Indicates, if set, that the DATX8 PLL has locked.
  [14:7] WLPRD — Write Leveling Period: Returns the DDR clock period measured by the write leveling LCDL during calibration. The measured period is used to generate the control of the write leveling pipeline which is a function of the write-leveling delay and the clock period. This value is PVT compensated
  [6] WLERR — Write Leveling Error: Indicates, if set, that there is a write leveling error in the DATX8.
  [5] WLDONE — Write Leveling Done: Indicates, if set, that the DATX8 has completed write leveling.
  [4] WLCAL — Write Leveling Calibration: Indicates, if set, that the DATX8 has finished doing period measurement calibration for the write leveling slave delay line
  [3] GDQSCAL — Read DQS gating Calibration: Indicates, if set, that the DATX8 has finished doing period measurement calibration for the read DQS gating LCDL.
  [2] RDQSNCAL — Read DQS# Calibration (Type B/B1 PHY Only): Indicates, if set, that the DATX8 has finished doing period measurement calibration for the read DQS# LCDL
  [1] RDQSCAL — Read DQS Calibration: Indicates, if set, that the DATX8 has finished doing period measurement calibration for the read DQS LCDL.
  [0] WDQCAL — Write DQ Calibration: Indicates, if set, that the DATX8 has finished doing period measurement calibration for the write DQ LCDL.
{0x1E0+0x40*i} DDR_PHY_DX{i}LCDLR0 rw (i=0..3)
  [8n+7:8n] R{n}WLD (n=0..3) — Rank {n} Write Leveling Delay: Rank {n} delay select for the write leveling (WL) LCDL
{0x1E4+0x40*i} DDR_PHY_DX{i}LCDLR1 (i=0..3)
  [31:24] RESERVED ro — Reads return zeros
  [23:16] RDQSND rw — Read DQSN Delay: Delay select for the read DQSN (RDQS) LCDL
  [15:8] RDQSD rw — Read DQS Delay: Delay select for the read DQS (RDQS) LCDL
  [7:0] WDQD rw — Write Data Delay: Delay select for the write data (WDQ) LCDL.
{0x1E8+0x40*i} DDR_PHY_DX{i}LCDLR2 rw (i=0..3)
  [8n+7:8n] R{n}DQSGD (n=0..3) — Rank {n} Read DQS Gating Delay: Rank {n} delay select for the read DQS gating (DQSG) LCDL.
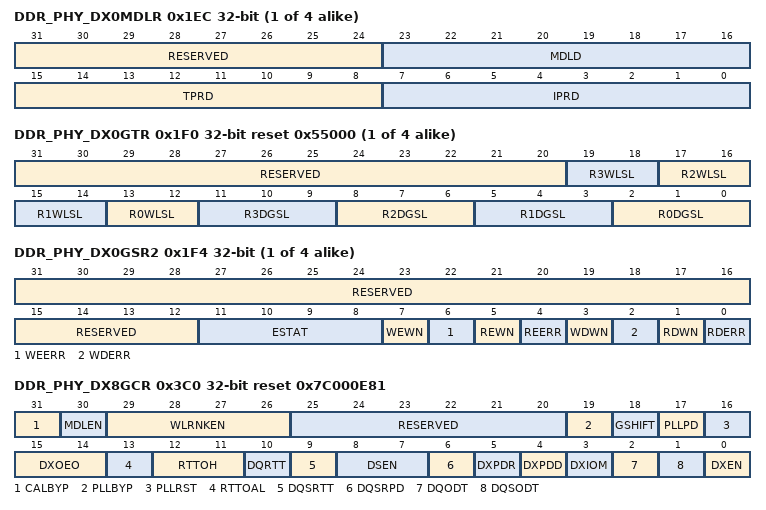
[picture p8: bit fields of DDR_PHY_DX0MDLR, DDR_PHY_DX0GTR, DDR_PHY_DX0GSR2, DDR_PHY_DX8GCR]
{0x1EC+0x40*i} DDR_PHY_DX{i}MDLR (i=0..3)
  [31:24] RESERVED ro — Reads return zeros
  [23:16] MDLD rw — MDL Delay: Delay select for the LCDL for the Master Delay Line.
  [15:8] TPRD rw — Target Period: Target period measured by the master delay line calibration for VT drift compensation. This is the current measured value of the period and is continuously updated if the MDL is enabled to do so.
  [7:0] IPRD rw — Initial Period: Initial period measured by the master delay line calibration for VT drift compensation. This value is used as the denominator when calculating the ratios of updates during VT compensation.
{0x1F0+0x40*i} DDR_PHY_DX{i}GTR reset 0x55000 (i=0..3)
  [31:20] RESERVED ro — Reads return zeros
  [19:18] R3WLSL rw — Rank n Write Leveling System Latency: This is used to adjust the write latency after write leveling. Power-up default is 01 (that is, no extra clock cycles required). The SL fields are initially set by the PUB during automatic write leveling but these values can be overwritten by a direct write to this register. Every two bits of this register control the latency of each of the (up to) four ranks. R0WLSL controls the latency of rank 0, R1WLSL controls rank 1, and so on. Valid values:
  [17:16] R2WLSL rw — See description for R3WLSL.
  [15:14] R1WLSL rw — See description for R3WLSL.
  [13:12] R0WLSL rw — See description for R3WLSL.
  [11:9] R3DGSL rw — Rank n DQS Gating System Latency: This is used to increase the number of clock cycles needed to expect valid DDR read data by up to seven extra clock cycles. This is used to compensate for board delays and other system delays. Power-up default is 000 (that is, no extra clock cycles required). The SL fields are initially set by the PHY during automatic DQS data training but these values can be overwritten by a direct write to this register. Every three bits of this register control the latency of each of the (up to) four ranks. R0DGSL controls the latency of rank 0, R1DGSL controls rank 1, and so on. Valid values are 0 to 7.
  [8:6] R2DGSL rw — See description for R3DGSL.
  [5:3] R1DGSL rw — See description for R3DGSL.
  [2:0] R0DGSL rw — See description for R3DGSL.
{0x1F4+0x40*i} DDR_PHY_DX{i}GSR2 ro (i=0..3)
  [31:12] RESERVED — Reads return zeros.
  [11:8] ESTAT — Error Status: If an error occurred for this lane as indicated by RDERR, WDERR, REERR or WEERR the error status code can provide additional information regard when the error occurred during the algorithm execution.
  [7] WEWN — Write Eye Centering Warning: Indicates, if set, that the byte lane
  [6] WEERR — Write Eye Centering Error: Indicates, if set, that the byte lane
  [5] REWN — Read Eye Centering Warning: Indicates, if set, that the byte lane
  [4] REERR — Read Eye Centering Error: Indicates, if set, that the byte lane
  [3] WDWN — Write Bit Deskew Warning: Indicates, if set, that the byte lane
  [2] WDERR — Write Bit Deskew Error: Indicates, if set, that the byte lane
  [1] RDWN — Read Bit Deskew Warning: Indicates, if set, that the byte lane
  [0] RDERR — Read Bit Deskew Error: Indicates, if set, that the byte lane
0x3C0 DDR_PHY_DX8GCR reset 0x7C000E81
  fields as DDR_PHY_DX0GCR
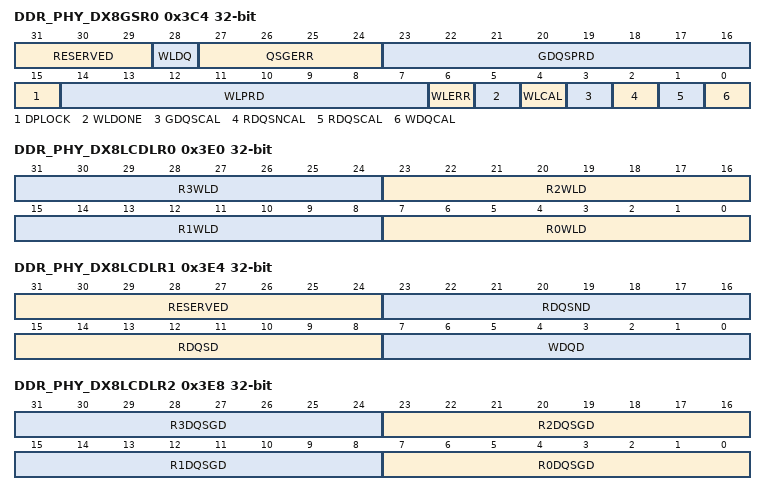
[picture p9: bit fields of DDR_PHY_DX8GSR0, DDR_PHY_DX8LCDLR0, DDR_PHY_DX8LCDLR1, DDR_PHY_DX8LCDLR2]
0x3C4 DDR_PHY_DX8GSR0 ro
  fields as DDR_PHY_DX0GSR0
0x3E0 DDR_PHY_DX8LCDLR0 rw
  fields as DDR_PHY_DX0LCDLR0
0x3E4 DDR_PHY_DX8LCDLR1
  fields as DDR_PHY_DX0LCDLR1
0x3E8 DDR_PHY_DX8LCDLR2 rw
  fields as DDR_PHY_DX0LCDLR2
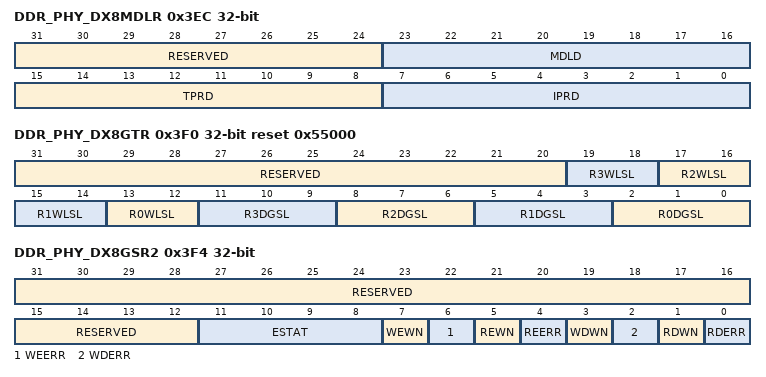
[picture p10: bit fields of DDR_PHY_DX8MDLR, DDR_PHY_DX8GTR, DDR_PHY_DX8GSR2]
0x3EC DDR_PHY_DX8MDLR
  fields as DDR_PHY_DX0MDLR
0x3F0 DDR_PHY_DX8GTR reset 0x55000
  fields as DDR_PHY_DX0GTR
0x3F4 DDR_PHY_DX8GSR2 ro
  fields as DDR_PHY_DX0GSR2
